VERSION ""

NS_ :

BS_:

BU_:

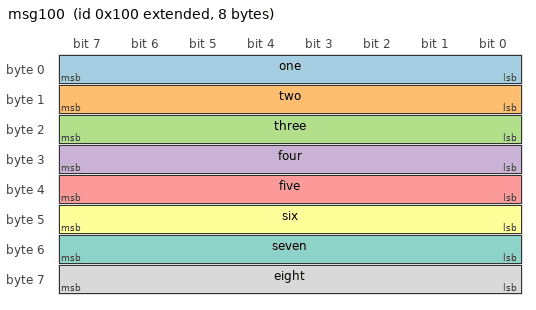
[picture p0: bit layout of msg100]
BO_ 2147483904 msg100: 8 Vector__XXX
	SG_ one : 0|8@1+ (1,0) [0|256] "ul" Vector__XXX
	SG_ two : 8|8@1+ (1,0) [0|256] "ul" Vector__XXX
	SG_ three : 16|8@1+ (1,0) [0|256] "ul" Vector__XXX
	SG_ four : 24|8@1+ (1,0) [0|256] "ul" Vector__XXX
	SG_ five : 32|8@1+ (1,0) [0|256] "ul" Vector__XXX
	SG_ six : 40|8@1+ (1,0) [0|256] "ul" Vector__XXX
	SG_ seven : 48|8@1+ (1,0) [0|256] "ul" Vector__XXX
	SG_ eight : 56|8@1+ (1,0) [0|256] "ul" Vector__XXX

CM_ BO_ 2147483904 "test message";
BA_DEF_ SG_  "SPN" INT 0 524287;
BA_DEF_ BO_  "VFrameFormat" ENUM  "StandardCAN","ExtendedCAN","reserved","J1939PG";
BA_DEF_  "DatabaseVersion" STRING ;
BA_DEF_  "BusType" STRING ;
BA_DEF_  "ProtocolType" STRING ;
BA_DEF_  "DatabaseCompiler" STRING ;
BA_DEF_DEF_  "SPN" 0;
BA_DEF_DEF_  "VFrameFormat" "J1939PG";
BA_DEF_DEF_  "DatabaseVersion" "DEMO PLUS";
BA_DEF_DEF_  "BusType" "";
BA_DEF_DEF_  "ProtocolType" "";
BA_DEF_DEF_  "DatabaseCompiler" "";
BA_ "ProtocolType" "J1939";
BA_ "BusType" "CAN";
BA_ "DatabaseCompiler" "CSS ELECTRONICS (WWW.CSSELECTRONICS.COM)";
BA_ "DatabaseVersion" "1.0.0";
BA_ "SPN" SG_ 2566844926 WheelBasedVehicleSpeed 84;
